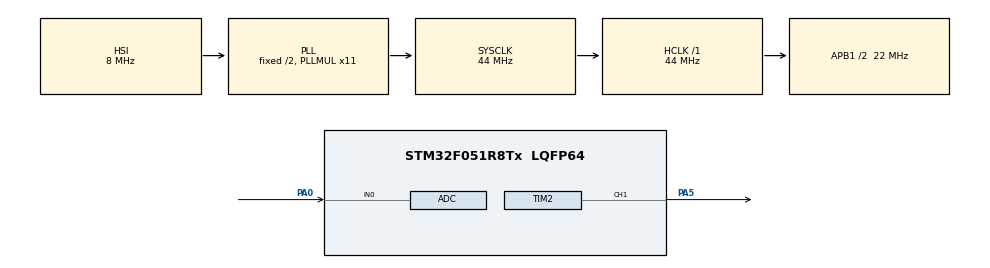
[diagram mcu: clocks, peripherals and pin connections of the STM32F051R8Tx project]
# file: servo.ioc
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ADC.ContinuousConvMode=ENABLE
ADC.Resolution=ADC_RESOLUTION_8B
ADC.SamplingTime=ADC_SAMPLETIME_28CYCLES_5
Mcu.Family=STM32F0
Mcu.Name=STM32F051R8Tx
Mcu.Package=LQFP64
NVIC.TIM2_IRQn=true\:0\:0\:false\:false\:true\:true\:true\:true
PA0.Mode=IN0
PA0.Signal=ADC_IN0
PA13.Mode=Serial_Wire
PA13.Signal=SYS_SWDIO
PA14.Mode=Serial_Wire
PA14.Signal=SYS_SWCLK
PA5.Signal=S_TIM2_CH1_ETR
PF0-OSC_IN.Mode=HSE-External-Oscillator
PF0-OSC_IN.Signal=RCC_OSC_IN
PF1-OSC_OUT.Mode=HSE-External-Oscillator
PF1-OSC_OUT.Signal=RCC_OSC_OUT
ProjectManager.HeapSize=0x200
ProjectManager.StackSize=0x400
ProjectManager.TargetToolchain=STM32CubeIDE
RCC.AHBFreq_Value=44000000
RCC.APB1CLKDivider=RCC_HCLK_DIV2
RCC.APB1Freq_Value=22000000
RCC.APB1TimFreq_Value=44000000
RCC.HCLKFreq_Value=44000000
RCC.PLLMUL=RCC_PLL_MUL11
RCC.SYSCLKFreq_VALUE=44000000
RCC.SYSCLKSource=RCC_SYSCLKSOURCE_PLLCLK
SH.S_TIM2_CH1_ETR.0=TIM2_CH1,PWM Generation1 CH1
TIM2.AutoReloadPreload=TIM_AUTORELOAD_PRELOAD_DISABLE
TIM2.Channel-PWM\ Generation1\ CH1=TIM_CHANNEL_1
TIM2.Period=1000-1
TIM2.Prescaler=880-1
VP_TIM2_VS_ClockSourceINT.Mode=Internal
board=STM32F0DISCOVERY

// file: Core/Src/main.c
/* USER CODE BEGIN Header */
/**
  ******************************************************************************
  * @file           : main.c
  * @brief          : Main program body
  ******************************************************************************
  * @attention
  *
  * Copyright (c) 2023 STMicroelectronics.
  * All rights reserved.
  *
  * This software is licensed under terms that can be found in the LICENSE file
  * in the root directory of this software component.
  * If no LICENSE file comes with this software, it is provided AS-IS.
  *
  ******************************************************************************
  */
/* USER CODE END Header */
#include "main.h"

ADC_HandleTypeDef hadc;

TIM_HandleTypeDef htim2;

void SystemClock_Config(void);
static void MX_GPIO_Init(void);
static void MX_TIM2_Init(void);
static void MX_ADC_Init(void);

/* USER CODE BEGIN 0 */
uint16_t adcvar,instance,PWM;
/* USER CODE END 0 */

int main(void)
{

  /* MCU Configuration--------------------------------------------------------*/

  /* Reset of all peripherals, Initializes the Flash interface and the Systick. */
  HAL_Init();

  /* Configure the system clock */
  SystemClock_Config();

  /* Initialize all configured peripherals */
  MX_GPIO_Init();
  MX_TIM2_Init();
  MX_ADC_Init();
  /* USER CODE BEGIN 2 */
  HAL_TIM_PWM_Start(&htim2, TIM_CHANNEL_1);
  HAL_ADC_Start(&hadc);
  /* USER CODE END 2 */

  /* Infinite loop */
  while (1)
  {

    /* USER CODE BEGIN 3 */

	  HAL_ADC_PollForConversion(&hadc, HAL_MAX_DELAY);
	  adcvar = HAL_ADC_GetValue(&hadc);
	  PWM = (adcvar/2)-1;
	  __HAL_TIM_SET_COMPARE(&htim2,TIM_CHANNEL_1, PWM);
	  HAL_Delay(50);

  }
  /* USER CODE END 3 */
}

void SystemClock_Config(void)
{
  RCC_OscInitTypeDef RCC_OscInitStruct = {0};
  RCC_ClkInitTypeDef RCC_ClkInitStruct = {0};

  /** Initializes the RCC Oscillators according to the specified parameters
  * in the RCC_OscInitTypeDef structure.
  */
  RCC_OscInitStruct.OscillatorType = RCC_OSCILLATORTYPE_HSI|RCC_OSCILLATORTYPE_HSI14;
  RCC_OscInitStruct.HSIState = RCC_HSI_ON;
  RCC_OscInitStruct.HSI14State = RCC_HSI14_ON;
  RCC_OscInitStruct.HSICalibrationValue = RCC_HSICALIBRATION_DEFAULT;
  RCC_OscInitStruct.HSI14CalibrationValue = 16;
  RCC_OscInitStruct.PLL.PLLState = RCC_PLL_ON;
  RCC_OscInitStruct.PLL.PLLSource = RCC_PLLSOURCE_HSI;
  RCC_OscInitStruct.PLL.PLLMUL = RCC_PLL_MUL11;
  RCC_OscInitStruct.PLL.PREDIV = RCC_PREDIV_DIV1;
  if (HAL_RCC_OscConfig(&RCC_OscInitStruct) != HAL_OK)
  {
    Error_Handler();
  }

  /** Initializes the CPU, AHB and APB buses clocks
  */
  RCC_ClkInitStruct.ClockType = RCC_CLOCKTYPE_HCLK|RCC_CLOCKTYPE_SYSCLK
                              |RCC_CLOCKTYPE_PCLK1;
  RCC_ClkInitStruct.SYSCLKSource = RCC_SYSCLKSOURCE_PLLCLK;
  RCC_ClkInitStruct.AHBCLKDivider = RCC_SYSCLK_DIV1;
  RCC_ClkInitStruct.APB1CLKDivider = RCC_HCLK_DIV2;

  if (HAL_RCC_ClockConfig(&RCC_ClkInitStruct, FLASH_LATENCY_1) != HAL_OK)
  {
    Error_Handler();
  }
}

static void MX_ADC_Init(void)
{

  ADC_ChannelConfTypeDef sConfig = {0};

  /** Configure the global features of the ADC (Clock, Resolution, Data Alignment and number of conversion)
  */
  hadc.Instance = ADC1;
  hadc.Init.ClockPrescaler = ADC_CLOCK_ASYNC_DIV1;
  hadc.Init.Resolution = ADC_RESOLUTION_8B;
  hadc.Init.DataAlign = ADC_DATAALIGN_RIGHT;
  hadc.Init.ScanConvMode = ADC_SCAN_DIRECTION_FORWARD;
  hadc.Init.EOCSelection = ADC_EOC_SINGLE_CONV;
  hadc.Init.LowPowerAutoWait = DISABLE;
  hadc.Init.LowPowerAutoPowerOff = DISABLE;
  hadc.Init.ContinuousConvMode = ENABLE;
  hadc.Init.DiscontinuousConvMode = DISABLE;
  hadc.Init.ExternalTrigConv = ADC_SOFTWARE_START;
  hadc.Init.ExternalTrigConvEdge = ADC_EXTERNALTRIGCONVEDGE_NONE;
  hadc.Init.DMAContinuousRequests = DISABLE;
  hadc.Init.Overrun = ADC_OVR_DATA_PRESERVED;
  if (HAL_ADC_Init(&hadc) != HAL_OK)
  {
    Error_Handler();
  }

  /** Configure for the selected ADC regular channel to be converted.
  */
  sConfig.Channel = ADC_CHANNEL_0;
  sConfig.Rank = ADC_RANK_CHANNEL_NUMBER;
  sConfig.SamplingTime = ADC_SAMPLETIME_28CYCLES_5;
  if (HAL_ADC_ConfigChannel(&hadc, &sConfig) != HAL_OK)
  {
    Error_Handler();
  }

}

static void MX_TIM2_Init(void)
{

  TIM_ClockConfigTypeDef sClockSourceConfig = {0};
  TIM_MasterConfigTypeDef sMasterConfig = {0};
  TIM_OC_InitTypeDef sConfigOC = {0};

  htim2.Instance = TIM2;
  htim2.Init.Prescaler = 880-1;
  htim2.Init.CounterMode = TIM_COUNTERMODE_UP;
  htim2.Init.Period = 1000-1;
  htim2.Init.ClockDivision = TIM_CLOCKDIVISION_DIV1;
  htim2.Init.AutoReloadPreload = TIM_AUTORELOAD_PRELOAD_DISABLE;
  if (HAL_TIM_Base_Init(&htim2) != HAL_OK)
  {
    Error_Handler();
  }
  sClockSourceConfig.ClockSource = TIM_CLOCKSOURCE_INTERNAL;
  if (HAL_TIM_ConfigClockSource(&htim2, &sClockSourceConfig) != HAL_OK)
  {
    Error_Handler();
  }
  if (HAL_TIM_PWM_Init(&htim2) != HAL_OK)
  {
    Error_Handler();
  }
  sMasterConfig.MasterOutputTrigger = TIM_TRGO_RESET;
  sMasterConfig.MasterSlaveMode = TIM_MASTERSLAVEMODE_DISABLE;
  if (HAL_TIMEx_MasterConfigSynchronization(&htim2, &sMasterConfig) != HAL_OK)
  {
    Error_Handler();
  }
  sConfigOC.OCMode = TIM_OCMODE_PWM1;
  sConfigOC.Pulse = 0;
  sConfigOC.OCPolarity = TIM_OCPOLARITY_HIGH;
  sConfigOC.OCFastMode = TIM_OCFAST_DISABLE;
  if (HAL_TIM_PWM_ConfigChannel(&htim2, &sConfigOC, TIM_CHANNEL_1) != HAL_OK)
  {
    Error_Handler();
  }
  HAL_TIM_MspPostInit(&htim2);

}

static void MX_GPIO_Init(void)
{

  /* GPIO Ports Clock Enable */
  __HAL_RCC_GPIOF_CLK_ENABLE();
  __HAL_RCC_GPIOA_CLK_ENABLE();

}

void Error_Handler(void)
{
  __disable_irq();
  while (1)
  {
  }
}
